AUTOSAR XML (schema 4-0-3)
package /DID_Component
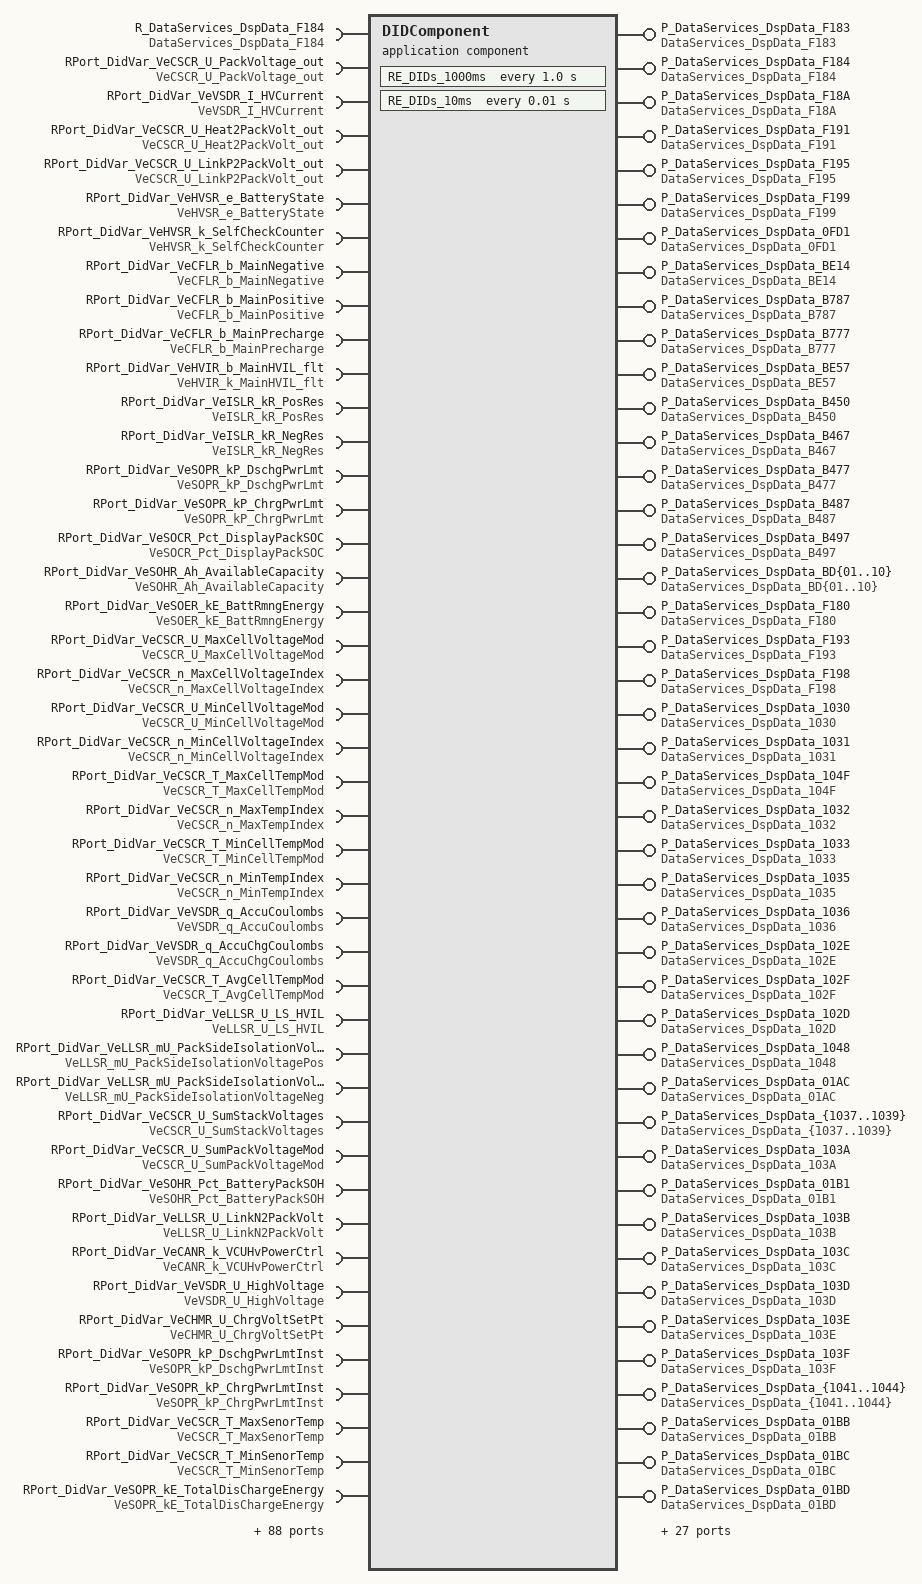
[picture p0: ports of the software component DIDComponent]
  application sw component type DIDComponent
    provide port P_DataServices_DspData_F183: provided-interface=DataServices_DspData_F183
    provide port P_DataServices_DspData_F184: provided-interface=DataServices_DspData_F184
    require port R_DataServices_DspData_F184: nonqueued-receiver-com-spec{data-element=Data, enable-update=true}, required-interface=DataServices_DspData_F184
    76 x provide port:
      P_DataServices_DspData_F18A: provided-interface=DataServices_DspData_F18A
      P_DataServices_DspData_F191: provided-interface=DataServices_DspData_F191
      P_DataServices_DspData_F195: provided-interface=DataServices_DspData_F195
      P_DataServices_DspData_F199: provided-interface=DataServices_DspData_F199
      P_DataServices_DspData_0FD1: provided-interface=DataServices_DspData_0FD1
      P_DataServices_DspData_BE14: provided-interface=DataServices_DspData_BE14
      P_DataServices_DspData_B787: provided-interface=DataServices_DspData_B787
      P_DataServices_DspData_B777: provided-interface=DataServices_DspData_B777
      P_DataServices_DspData_BE57: provided-interface=DataServices_DspData_BE57
      P_DataServices_DspData_B450: provided-interface=DataServices_DspData_B450
      P_DataServices_DspData_B467: provided-interface=DataServices_DspData_B467
      P_DataServices_DspData_B477: provided-interface=DataServices_DspData_B477
      P_DataServices_DspData_B487: provided-interface=DataServices_DspData_B487
      P_DataServices_DspData_B497: provided-interface=DataServices_DspData_B497
      P_DataServices_DspData_BD{01..10}: provided-interface=DataServices_DspData_BD{01..10}
      P_DataServices_DspData_F180: provided-interface=DataServices_DspData_F180
      P_DataServices_DspData_F193: provided-interface=DataServices_DspData_F193
      P_DataServices_DspData_F198: provided-interface=DataServices_DspData_F198
      P_DataServices_DspData_1030: provided-interface=DataServices_DspData_1030
      P_DataServices_DspData_1031: provided-interface=DataServices_DspData_1031
      P_DataServices_DspData_104F: provided-interface=DataServices_DspData_104F
      P_DataServices_DspData_1032: provided-interface=DataServices_DspData_1032
      P_DataServices_DspData_1033: provided-interface=DataServices_DspData_1033
      P_DataServices_DspData_1035: provided-interface=DataServices_DspData_1035
      P_DataServices_DspData_1036: provided-interface=DataServices_DspData_1036
      P_DataServices_DspData_102E: provided-interface=DataServices_DspData_102E
      P_DataServices_DspData_102F: provided-interface=DataServices_DspData_102F
      P_DataServices_DspData_102D: provided-interface=DataServices_DspData_102D
      P_DataServices_DspData_1048: provided-interface=DataServices_DspData_1048
      P_DataServices_DspData_01AC: provided-interface=DataServices_DspData_01AC
      P_DataServices_DspData_{1037..1039}: provided-interface=DataServices_DspData_{1037..1039}
      P_DataServices_DspData_103A: provided-interface=DataServices_DspData_103A
      P_DataServices_DspData_01B1: provided-interface=DataServices_DspData_01B1
      P_DataServices_DspData_103B: provided-interface=DataServices_DspData_103B
      P_DataServices_DspData_103C: provided-interface=DataServices_DspData_103C
      P_DataServices_DspData_103D: provided-interface=DataServices_DspData_103D
      P_DataServices_DspData_103E: provided-interface=DataServices_DspData_103E
      P_DataServices_DspData_103F: provided-interface=DataServices_DspData_103F
      P_DataServices_DspData_{1041..1044}: provided-interface=DataServices_DspData_{1041..1044}
      P_DataServices_DspData_01BB: provided-interface=DataServices_DspData_01BB
      P_DataServices_DspData_01BC: provided-interface=DataServices_DspData_01BC
      P_DataServices_DspData_01BD: provided-interface=DataServices_DspData_01BD
      P_DataServices_DspData_01BE: provided-interface=DataServices_DspData_01BE
      P_DataServices_DspData_01BF: provided-interface=DataServices_DspData_01BF
      P_DataServices_DspData_01C0: provided-interface=DataServices_DspData_01C0
      P_DataServices_DspData_{1045..1047}: provided-interface=DataServices_DspData_{1045..1047}
      P_DataServices_DspData_01D9: provided-interface=DataServices_DspData_01D9
      P_DataServices_DspData_01DA: provided-interface=DataServices_DspData_01DA
      P_DataServices_DspData_01DC: provided-interface=DataServices_DspData_01DC
      P_DataServices_DspData_01DD: provided-interface=DataServices_DspData_01DD
      P_DataServices_DspData_01E4: provided-interface=DataServices_DspData_01E4
      P_DataServices_DspData_01E5: provided-interface=DataServices_DspData_01E5
      P_DataServices_DspData_1049: provided-interface=DataServices_DspData_1049
      P_DataServices_DspData_01E{7..9}: provided-interface=DataServices_DspData_01E{7..9}
      P_DataServices_DspData_01EA: provided-interface=DataServices_DspData_01EA
      P_DataServices_DspData_104A: provided-interface=DataServices_DspData_104A
      P_DataServices_DspData_104B: provided-interface=DataServices_DspData_104B
      P_DataServices_DspData_104E: provided-interface=DataServices_DspData_104E
    34 x require port:
      RPort_DidVar_VeCSCR_U_PackVoltage_out: required-interface=VeCSCR_U_PackVoltage_out
      RPort_DidVar_VeVSDR_I_HVCurrent: required-interface=VeVSDR_I_HVCurrent
      RPort_DidVar_VeCSCR_U_Heat2PackVolt_out: required-interface=VeCSCR_U_Heat2PackVolt_out
      RPort_DidVar_VeCSCR_U_LinkP2PackVolt_out: required-interface=VeCSCR_U_LinkP2PackVolt_out
      RPort_DidVar_VeHVSR_e_BatteryState: required-interface=VeHVSR_e_BatteryState
      RPort_DidVar_VeHVSR_k_SelfCheckCounter: required-interface=VeHVSR_k_SelfCheckCounter
      RPort_DidVar_VeCFLR_b_MainNegative: required-interface=VeCFLR_b_MainNegative
      RPort_DidVar_VeCFLR_b_MainPositive: required-interface=VeCFLR_b_MainPositive
      RPort_DidVar_VeCFLR_b_MainPrecharge: required-interface=VeCFLR_b_MainPrecharge
      RPort_DidVar_VeHVIR_b_MainHVIL_flt: required-interface=VeHVIR_k_MainHVIL_flt
      RPort_DidVar_VeISLR_kR_PosRes: required-interface=VeISLR_kR_PosRes
      RPort_DidVar_VeISLR_kR_NegRes: required-interface=VeISLR_kR_NegRes
      RPort_DidVar_VeSOPR_kP_DschgPwrLmt: required-interface=VeSOPR_kP_DschgPwrLmt
      RPort_DidVar_VeSOPR_kP_ChrgPwrLmt: required-interface=VeSOPR_kP_ChrgPwrLmt
      RPort_DidVar_VeSOCR_Pct_DisplayPackSOC: required-interface=VeSOCR_Pct_DisplayPackSOC
      RPort_DidVar_VeSOHR_Ah_AvailableCapacity: required-interface=VeSOHR_Ah_AvailableCapacity
      RPort_DidVar_VeSOER_kE_BattRmngEnergy: required-interface=VeSOER_kE_BattRmngEnergy
      RPort_DidVar_VeCSCR_U_MaxCellVoltageMod: required-interface=VeCSCR_U_MaxCellVoltageMod
      RPort_DidVar_VeCSCR_n_MaxCellVoltageIndex: required-interface=VeCSCR_n_MaxCellVoltageIndex
      RPort_DidVar_VeCSCR_U_MinCellVoltageMod: required-interface=VeCSCR_U_MinCellVoltageMod
      RPort_DidVar_VeCSCR_n_MinCellVoltageIndex: required-interface=VeCSCR_n_MinCellVoltageIndex
      RPort_DidVar_VeCSCR_T_MaxCellTempMod: required-interface=VeCSCR_T_MaxCellTempMod
      RPort_DidVar_VeCSCR_n_MaxTempIndex: required-interface=VeCSCR_n_MaxTempIndex
      RPort_DidVar_VeCSCR_T_MinCellTempMod: required-interface=VeCSCR_T_MinCellTempMod
      RPort_DidVar_VeCSCR_n_MinTempIndex: required-interface=VeCSCR_n_MinTempIndex
      RPort_DidVar_VeVSDR_q_AccuCoulombs: required-interface=VeVSDR_q_AccuCoulombs
      RPort_DidVar_VeVSDR_q_AccuChgCoulombs: required-interface=VeVSDR_q_AccuChgCoulombs
      RPort_DidVar_VeCSCR_T_AvgCellTempMod: required-interface=VeCSCR_T_AvgCellTempMod
      RPort_DidVar_VeLLSR_U_LS_HVIL: required-interface=VeLLSR_U_LS_HVIL
      RPort_DidVar_VeLLSR_mU_PackSideIsolationVoltagePos: required-interface=VeLLSR_mU_PackSideIsolationVoltagePos
      RPort_DidVar_VeLLSR_mU_PackSideIsolationVoltageNeg: required-interface=VeLLSR_mU_PackSideIsolationVoltageNeg
      RPort_DidVar_VeCSCR_U_SumStackVoltages: required-interface=VeCSCR_U_SumStackVoltages
      RPort_DidVar_VeCSCR_U_SumPackVoltageMod: required-interface=VeCSCR_U_SumPackVoltageMod
      RPort_DidVar_VeSOHR_Pct_BatteryPackSOH: required-interface=VeSOHR_Pct_BatteryPackSOH
    4 x provide port:
      PPort_DID_F1F0: provided-interface=DataServices_DcmDspData_F1F0
      PPort_DID_F1AA: provided-interface=DataServices_DcmDspData_F1AA
      PPort_DID_F1A9: provided-interface=DataServices_DcmDspData_F1A9
      PPort_DID_F1A5: provided-interface=DataServices_DcmDspData_F1A5
    16 x require port:
      RPort_DidVar_VeLLSR_U_LinkN2PackVolt: required-interface=VeLLSR_U_LinkN2PackVolt
      RPort_DidVar_VeCANR_k_VCUHvPowerCtrl: required-interface=VeCANR_k_VCUHvPowerCtrl
      RPort_DidVar_VeVSDR_U_HighVoltage: required-interface=VeVSDR_U_HighVoltage
      RPort_DidVar_VeCHMR_U_ChrgVoltSetPt: required-interface=VeCHMR_U_ChrgVoltSetPt
      RPort_DidVar_VeSOPR_kP_DschgPwrLmtInst: required-interface=VeSOPR_kP_DschgPwrLmtInst
      RPort_DidVar_VeSOPR_kP_ChrgPwrLmtInst: required-interface=VeSOPR_kP_ChrgPwrLmtInst
      RPort_DidVar_VeCSCR_T_MaxSenorTemp: required-interface=VeCSCR_T_MaxSenorTemp
      RPort_DidVar_VeCSCR_T_MinSenorTemp: required-interface=VeCSCR_T_MinSenorTemp
      RPort_DidVar_VeSOPR_kE_TotalDisChargeEnergy: required-interface=VeSOPR_kE_TotalDisChargeEnergy
      RPort_DidVar_VeSOPR_kE_TotalChargeEnergy: required-interface=VeSOPR_kE_TotalChargeEnergy
      RPort_DidVar_VeLLSR_b_VCU_Wake: required-interface=VeLLSR_b_VCU_Wake
      RPort_DidVar_VeLLSR_U_KL30Volt: required-interface=VeLLSR_U_KL30Volt
      RPort_DidVar_VeISLR_kR_IsolationResistance: required-interface=VeISLR_kR_InsolationResistance
      RPort_DidVar_VeLLSR_U_HS_HVIL: required-interface=VeLLSR_U_HS_HVIL
      RPort_DidVar_VaCLBR_b_ActivateBalancing: required-interface=VaCLBR_b_ActivateBalancing
      RPort_DidVar_VeLLSR_U_HS_FCHVIL: required-interface=VeLLSR_U_HS_FCHVIL
    6 x provide port:
      P_DataServices_DspData_F192: provided-interface=DataServices_DspData_F192
      P_DataServices_DspData_F188: provided-interface=DataServices_DspData_F188
      P_DataServices_DspData_1000: provided-interface=DataServices_DspData_1000
      P_DataServices_DspData_1020: provided-interface=DataServices_DspData_1020
      P_DataServices_DspData_1040: provided-interface=DataServices_DspData_1040
      P_DataServices_DspData_1034: provided-interface=DataServices_DspData_1034
    4 x require port:
      RPort_DidVar_VeHVSR_k_BMSSts: required-interface=VeHVSR_k_BMSSts
      RPort_DidVar_VeCHMR_I_ChrgCurrentMax: required-interface=VeCHMR_I_ChrgCurrentMax
      RPort_DidVar_VeSOPR_kE_SingleDisChargeEnergy: required-interface=VeSOPR_kE_SingleDisChargeEnergy
      RPort_DidVar_VeSOPR_kE_SingleChargeEnergy: required-interface=VeSOPR_kE_SingleChargeEnergy
    provide port P_DataServices_DspData_F194: provided-interface=DataServices_DspData_F194
    77 x require port:
      RPort_DidVar_VeCPLR_k_DeltaCV_L2_flt: required-interface=VeCPLR_k_DeltaCV_L2_flt
      RPort_DidVar_VeCPLR_k_DeltaCV_L1_flt: required-interface=VeCPLR_k_DeltaCV_L1_flt
      RPort_DidVar_VeCPLR_k_UnderCV_L4_flt: required-interface=VeCPLR_k_UnderCV_L4_flt
      RPort_DidVar_VeCPLR_k_UnderCV_L3_flt: required-interface=VeCPLR_k_UnderCV_L3_flt
      RPort_DidVar_VeCPLR_k_UnderCV_L2_flt: required-interface=VeCPLR_k_UnderCV_L2_flt
      RPort_DidVar_VeCPLR_k_OverCV_L4_flt: required-interface=VeCPLR_k_OverCV_L4_flt
      RPort_DidVar_VeCPLR_k_OverCV_L3_flt: required-interface=VeCPLR_k_OverCV_L3_flt
      RPort_DidVar_VeCPLR_k_OverCV_L1_flt: required-interface=VeCPLR_k_OverCV_L1_flt
      RPort_DidVar_VeCPLR_k_OverCT_L4_flt: required-interface=VeCPLR_k_OverCT_L4_flt
      RPort_DidVar_VeCPLR_k_OverCT_L3_flt: required-interface=VeCPLR_k_OverCT_L3_flt
      RPort_DidVar_VeCPLR_k_OverCT_L1_flt: required-interface=VeCPLR_k_OverCT_L1_flt
      RPort_DidVar_VeCPLR_k_PackUnderVolt_L3_flt: required-interface=VeCPLR_k_PackUnderVolt_L3_flt
      RPort_DidVar_VeCPLR_k_PackUnderVolt_L2_flt: required-interface=VeCPLR_k_PackUnderVolt_L2_flt
      RPort_DidVar_VeCPLR_k_PackOverVolt_L3_flt: required-interface=VeCPLR_k_PackOverVolt_L3_flt
      RPort_DidVar_VeCPLR_k_PackOverVolt_L1_flt: required-interface=VeCPLR_k_PackOverVolt_L1_flt
      RPort_DidVar_VeCPLR_k_DeltaCV_L3_flt: required-interface=VeCPLR_k_DeltaCV_L3_flt
      RPort_DidVar_VeSOPR_k_PackOverDchrgPower2_flt: required-interface=VeSOPR_k_PackOverDchrgPower2_flt
      RPort_DidVar_VeSOPR_k_PackOverDchrgPower1_flt: required-interface=VeSOPR_k_PackOverDchrgPower1_flt
      RPort_DidVar_VeCPLR_k_DeltaCT_L3_flt: required-interface=VeCPLR_k_DeltaCT_L3_flt
      RPort_DidVar_VeCPLR_k_DeltaCT_L2_flt: required-interface=VeCPLR_k_DeltaCT_L2_flt
      RPort_DidVar_VeCPLR_k_DeltaCT_L1_flt: required-interface=VeCPLR_k_DeltaCT_L1_flt
      RPort_DidVar_VeCPLR_k_UnderCT_L4_flt: required-interface=VeCPLR_k_UnderCT_L4_flt
      RPort_DidVar_VeCPLR_k_UnderCT_L3_flt: required-interface=VeCPLR_k_UnderCT_L3_flt
      RPort_DidVar_VeCPLR_k_UnderCT_L1_flt: required-interface=VeCPLR_k_UnderCT_L1_flt
      RPort_DidVar_VeSOCR_k_SOC_low3_flt: required-interface=VeSOCR_k_SOC_low3_flt
      RPort_DidVar_VeSOCR_k_SOC_low2_flt: required-interface=VeSOCR_k_SOC_low2_flt
      RPort_DidVar_VeSOCR_k_SOC_low1_flt: required-interface=VeSOCR_k_SOC_low1_flt
      RPort_DidVar_VeCHMR_k_ChrgOverCurr_level3_flt: required-interface=VeCHMR_k_ChrgOverCurr_level3_flt
      RPort_DidVar_VeSOPR_k_PackOverChrgPower3_flt: required-interface=VeSOPR_k_PackOverChrgPower3_flt
      RPort_DidVar_VeSOPR_k_PackOverChrgPower2_flt: required-interface=VeSOPR_k_PackOverChrgPower2_flt
      RPort_DidVar_VeSOPR_k_PackOverChrgPower1_flt: required-interface=VeSOPR_k_PackOverChrgPower1_flt
      RPort_DidVar_VeSOPR_k_PackOverDchrgPower3_flt: required-interface=VeSOPR_k_PackOverDchrgPower3_flt
      RPort_DidVar_VeCSCR_k_StackCircuit_flt: required-interface=VeCSCR_k_StackCircuit_flt
      RPort_DidVar_VeCSCR_k_CellCircuit_flt: required-interface=VeCSCR_k_CellCircuit_flt
      RPort_DidVar_VeISLR_k_Isolation_flt: required-interface=VeISLR_k_Isolation_flt
      RPort_DidVar_VeISLR_k_Isolation_L2_flt: required-interface=VeISLR_k_Isolation_L2_flt
      RPort_DidVar_VeISLR_k_Isolation_L1_flt: required-interface=VeISLR_k_Isolation_L1_flt
      RPort_DidVar_VeSOCR_k_SOCOverWarn_flt: required-interface=VeSOCR_k_SOCOverWarn_flt
      RPort_DidVar_VeSOCR_k_SOCJumpWarn_flt: required-interface=VeSOCR_k_SOCJumpWarn_flt
      RPort_DidVar_VeSOHR_k_LowSOH_flt: required-interface=VeSOHR_k_LowSOH_flt
      RPort_DidVar_VeLLSR_k_DaisyCom_flt: required-interface=VeLLSR_k_DaisyCom_flt
      RPort_DidVar_VeLLSR_k_BMS_CrashOutputSts: required-interface=VeLLSR_k_BMS_CrashOutputSts
      RPort_DidVar_VeLLSR_k_PackCrntCircuit_flt: required-interface=VeLLSR_k_PackCrntCircuit_flt
      RPort_DidVar_VeCSCR_k_TempArray_flt: required-interface=VeCSCR_k_TempArray_flt
      RPort_DidVar_VeCFLR_k_NegativeStuckClose_flt: required-interface=VeCFLR_k_NegativeStuckClose_flt
      RPort_DidVar_VeCFLR_k_ConDrvPosCircuit_flt: required-interface=VeCFLR_k_ConDrvPosCircuit_flt
      RPort_DidVar_VeCFLR_k_PositiveStuckOpen_flt: required-interface=VeCFLR_k_PositiveStuckOpen_flt
      RPort_DidVar_VeCFLR_k_PositiveStuckClose_flt: required-interface=VeCFLR_k_PositiveStuckClose_flt
      RPort_DidVar_VeCFLR_k_ConDrvHeatCircuit_flt: required-interface=VeCFLR_k_ConDrvHeatCircuit_flt
      RPort_DidVar_VeCFLR_k_HeatStuckOpen_flt: required-interface=VeCFLR_k_HeatStuckOpen_flt
      RPort_DidVar_VeCFLR_k_HeatStuckClose_flt: required-interface=VeCFLR_k_HeatStuckClose_flt
      RPort_DidVar_VeCFLR_k_ConDrvPreCircuit_flt: required-interface=VeCFLR_k_ConDrvPreCircuit_flt
      RPort_DidVar_VeCFLR_k_PrechargeStuckOpen_flt: required-interface=VeCFLR_k_PrechargeStuckOpen_flt
      RPort_DidVar_VeCFLR_k_PrechargeStuckClose_flt: required-interface=VeCFLR_k_PrechargeStuckClose_flt
      RPort_DidVar_VeCFLR_k_ConDrvNegCircuit_flt: required-interface=VeCFLR_k_ConDrvNegCircuit_flt
      RPort_DidVar_VeCFLR_k_NegativeStuckOpen_flt: required-interface=VeCFLR_k_NegativeStuckOpen_flt
      RPort_DidVar_VeCSCR_k_LinkNVolt_flt: required-interface=VeCSCR_k_LinkNVolt_flt
      RPort_DidVar_VeCSCR_k_HeatVolt_flt: required-interface=VeCSCR_k_HeatVolt_flt
      RPort_DidVar_VeCSCR_k_LinkPVolt_flt: required-interface=VeCSCR_k_LinkPVolt_flt
      RPort_DidVar_VeCSCR_k_PackVolt_flt: required-interface=VeCSCR_k_PackVolt_flt
      RPort_DidVar_VeLLSR_k_ExtEEP_flt: required-interface=VeLLSR_k_ExtEEP_flt
      RPort_DidVar_VeLLSR_k_IntEEP_flt: required-interface=VeLLSR_k_IntEEP_flt
      RPort_DidVar_VeCFLR_k_MainFuse2Open_flt: required-interface=VeCFLR_k_MainFuse2Open_flt
      RPort_DidVar_VeCFLR_k_MainFuse1Open_flt: required-interface=VeCFLR_k_MainFuse1Open_flt
      RPort_DidVar_VeCPLR_k_PCBOverTemp_flt: required-interface=VeCPLR_k_PCBOverTemp_flt
      RPort_DidVar_VeCSCR_k_PCBTempInv_Flt: required-interface=VeCSCR_k_PCBTempInv_Flt
      RPort_DidVar_VeLLSR_k_BalOverTemp_flt: required-interface=VeLLSR_k_BalOverTemp_flt
      RPort_DidVar_VeCSCR_k_CBCircuit_flt: required-interface=VeCSCR_k_CBCircuit_flt
      RPort_DidVar_VeCFLR_k_PreChargeFail_flt: required-interface=VeCFLR_k_PreChargeFail_flt
      RPort_DidVar_VeCFLR_k_PreResistorStuckOpen_flt: required-interface=VeCFLR_k_PreResistorStuckOpen_flt
      RPort_DidVar_VeVSDR_k_PackVoltageInRange_flt: required-interface=VeVSDR_k_PackVoltageInRange_flt
      RPort_DidVar_VeVSDR_k_LinkVoltageInRange_flt: required-interface=VeVSDR_k_LinkVoltageInRange_flt
      RPort_DidVar_VeHVIR_k_MainHVIL2_flt: required-interface=VeHVIR_k_MainHVIL2_flt
      RPort_DidVar_VeTHMR_k_HeatTempRiseFast_flt: required-interface=VeTHMR_k_HeatTempRiseFast_flt
      RPort_DidVar_VeCPLR_k_ThermalRunaway_flt: required-interface=VeCPLR_k_ThermalRunaway_flt
      RPort_DidVar_VeLLSR_k_AbnormalShutdownDetected: required-interface=VeLLSR_k_AbnormalShutdownDetected
      RPort_DidVar_VeCFLR_k_UnexpectedContOpen_flt: required-interface=VeCFLR_k_UnexpectedContOpen_flt
    behavior IB_DIDCmpt: data-type-mapping=[HVIR_CodeDataTypeMappingsSet, ISLR_CodeDataTypeMappingsSet, VSDR_CodeDataTypeMappingsSet, CLBR_CodeDataTypeMappingsSet, SOER_CodeDataTypeMappingsSet, SOPR_CodeDataTypeMappingsSet, CSCR_CodeDataTypeMappingsSet, HMIR_CodeDataTypeMappingsSet, CFLR_CodeDataTypeMappingsSet, DHSR_CodeDataTypeMappingsSet, SOCR_CodeDataTypeMappingsSet, SOHR_CodeDataTypeMappingsSet, HVSR_CodeDataTypeMappingsSet, CHMR_CodeDataTypeMappingsSet, CPLR_CodeDataTypeMappingsSet, THMR_CodeDataTypeMappingsSet]
      timing event TimingEvent_DIDs_1000ms: start-on-event=RE_DIDs_1000ms, period=1.0
      timing event TimingEvent_DIDs_10ms: start-on-event=RE_DIDs_10ms, period=0.01
      per instance memory PIM_Did_01FF: implementation-data-type=DcmDspDidSize_DspData_01FF, type=NeDIDR_PartNo_01FF, type-definition=DcmDspDidSize_DspData_01FF
      runnable RE_DIDs_1000ms: symbol=RE_DID_Process1000ms
        data-read-access:
          131 x access:
            DataReadPoints_VeCSCR_U_PackVoltage_out: accessed-variable=RPort_DidVar_VeCSCR_U_PackVoltage_out.VeCSCR_U_PackVoltage_out
            DataReadPoints_VeVSDR_I_HVCurrent: accessed-variable=RPort_DidVar_VeVSDR_I_HVCurrent.VeVSDR_I_HVCurrent
            DataReadPoints_VeCSCR_U_Heat2PackVolt_out: accessed-variable=RPort_DidVar_VeCSCR_U_Heat2PackVolt_out.VeCSCR_U_Heat2PackVolt_out
            DataReadPoints_VeCSCR_U_LinkP2PackVolt_out: accessed-variable=RPort_DidVar_VeCSCR_U_LinkP2PackVolt_out.VeCSCR_U_LinkP2PackVolt_out
            DataReadPoints_VeHVSR_e_BatteryState: accessed-variable=RPort_DidVar_VeHVSR_e_BatteryState.VeHVSR_e_BatteryState
            DataReadPoints_VeHVSR_k_SelfCheckCounter: accessed-variable=RPort_DidVar_VeHVSR_k_SelfCheckCounter.VeHVSR_k_SelfCheckCounter
            DataReadPoints_VeCFLR_b_MainNegative: accessed-variable=RPort_DidVar_VeCFLR_b_MainNegative.VeCFLR_b_MainNegative
            DataReadPoints_VeCFLR_b_MainPositive: accessed-variable=RPort_DidVar_VeCFLR_b_MainPositive.VeCFLR_b_MainPositive
            DataReadPoints_VeCFLR_b_MainPrecharge: accessed-variable=RPort_DidVar_VeCFLR_b_MainPrecharge.VeCFLR_b_MainPrecharge
            DataReadPoints_VeHVIR_b_MainHVIL_flt: accessed-variable=RPort_DidVar_VeHVIR_b_MainHVIL_flt.VeHVIR_k_MainHVIL_flt
            DataReadPoints_VeISLR_kR_PosRes: accessed-variable=RPort_DidVar_VeISLR_kR_PosRes.VeISLR_kR_PosRes
            DataReadPoints_VeISLR_kR_NegRes: accessed-variable=RPort_DidVar_VeISLR_kR_NegRes.VeISLR_kR_NegRes
            DataReadPoints_VeSOPR_kP_DschgPwrLmt: accessed-variable=RPort_DidVar_VeSOPR_kP_DschgPwrLmt.VeSOPR_kP_DschgPwrLmt
            DataReadPoints_VeSOPR_kP_ChrgPwrLmt: accessed-variable=RPort_DidVar_VeSOPR_kP_ChrgPwrLmt.VeSOPR_kP_ChrgPwrLmt
            DataReadPoints_VeSOCR_Pct_DisplayPackSOC: accessed-variable=RPort_DidVar_VeSOCR_Pct_DisplayPackSOC.VeSOCR_Pct_DisplayPackSOC
            DataReadPoints_VeSOHR_Ah_AvailableCapacity: accessed-variable=RPort_DidVar_VeSOHR_Ah_AvailableCapacity.VeSOHR_Ah_AvailableCapacity
            DataReadPoints_VeSOER_kE_BattRmngEnergy: accessed-variable=RPort_DidVar_VeSOER_kE_BattRmngEnergy.VeSOER_kE_BattRmngEnergy
            DataReadPoints_VeCSCR_U_MaxCellVoltageMod: accessed-variable=RPort_DidVar_VeCSCR_U_MaxCellVoltageMod.VeCSCR_U_MaxCellVoltageMod
            DataReadPoints_VeCSCR_n_MaxCellVoltageIndex: accessed-variable=RPort_DidVar_VeCSCR_n_MaxCellVoltageIndex.VeCSCR_n_MaxCellVoltageIndex
            DataReadPoints_VeCSCR_U_MinCellVoltageMod: accessed-variable=RPort_DidVar_VeCSCR_U_MinCellVoltageMod.VeCSCR_U_MinCellVoltageMod
            DataReadPoints_VeCSCR_n_MinCellVoltageIndex: accessed-variable=RPort_DidVar_VeCSCR_n_MinCellVoltageIndex.VeCSCR_n_MinCellVoltageIndex
            DataReadPoints_VeCSCR_T_MaxCellTempMod: accessed-variable=RPort_DidVar_VeCSCR_T_MaxCellTempMod.VeCSCR_T_MaxCellTempMod
            DataReadPoints_VeCSCR_n_MaxTempIndex: accessed-variable=RPort_DidVar_VeCSCR_n_MaxTempIndex.VeCSCR_n_MaxTempIndex
            DataReadPoints_VeCSCR_T_MinCellTempMod: accessed-variable=RPort_DidVar_VeCSCR_T_MinCellTempMod.VeCSCR_T_MinCellTempMod
            DataReadPoints_VeCSCR_n_MinTempIndex: accessed-variable=RPort_DidVar_VeCSCR_n_MinTempIndex.VeCSCR_n_MinTempIndex
            DataReadPoints_VeVSDR_q_AccuCoulombs: accessed-variable=RPort_DidVar_VeVSDR_q_AccuCoulombs.VeVSDR_q_AccuCoulombs
            DataReadPoints_VeVSDR_q_AccuChgCoulombs: accessed-variable=RPort_DidVar_VeVSDR_q_AccuChgCoulombs.VeVSDR_q_AccuChgCoulombs
            DataReadPoints_VeCSCR_T_AvgCellTempMod: accessed-variable=RPort_DidVar_VeCSCR_T_AvgCellTempMod.VeCSCR_T_AvgCellTempMod
            DataReadPoints_VeLLSR_U_LS_HVIL: accessed-variable=RPort_DidVar_VeLLSR_U_LS_HVIL.VeLLSR_U_LS_HVIL
            DataReadPoints_VeLLSR_mU_PackSideIsolationVoltagePos: accessed-variable=RPort_DidVar_VeLLSR_mU_PackSideIsolationVoltagePos.VeLLSR_mU_PackSideIsolationVoltagePos
            DataReadPoints_VeLLSR_mU_PackSideIsolationVoltageNeg: accessed-variable=RPort_DidVar_VeLLSR_mU_PackSideIsolationVoltageNeg.VeLLSR_mU_PackSideIsolationVoltageNeg
            DataReadPoints_VeCSCR_U_SumStackVoltages: accessed-variable=RPort_DidVar_VeCSCR_U_SumStackVoltages.VeCSCR_U_SumStackVoltages
            DataReadPoints_VeCSCR_U_SumPackVoltageMod: accessed-variable=RPort_DidVar_VeCSCR_U_SumPackVoltageMod.VeCSCR_U_SumPackVoltageMod
            DataReadPoints_VeSOHR_Pct_BatteryPackSOH: accessed-variable=RPort_DidVar_VeSOHR_Pct_BatteryPackSOH.VeSOHR_Pct_BatteryPackSOH
            DRA_VeLLSR_U_LinkN2PackVolt_0: accessed-variable=RPort_DidVar_VeLLSR_U_LinkN2PackVolt.VeLLSR_U_LinkN2PackVolt
            DRA_VeCANR_k_VCUHvPowerCtrl_0: accessed-variable=RPort_DidVar_VeCANR_k_VCUHvPowerCtrl.VeCANR_k_VCUHvPowerCtrl
            DRA_VeVSDR_U_HighVoltage_0: accessed-variable=RPort_DidVar_VeVSDR_U_HighVoltage.VeVSDR_U_HighVoltage
            DRA_VeCHMR_U_ChrgVoltSetPt_0: accessed-variable=RPort_DidVar_VeCHMR_U_ChrgVoltSetPt.VeCHMR_U_ChrgVoltSetPt
            DRA_VeSOPR_kP_DschgPwrLmtInst_0: accessed-variable=RPort_DidVar_VeSOPR_kP_DschgPwrLmtInst.VeSOPR_kP_DschgPwrLmtInst
            DRA_VeSOPR_kP_ChrgPwrLmtInst_0: accessed-variable=RPort_DidVar_VeSOPR_kP_ChrgPwrLmtInst.VeSOPR_kP_ChrgPwrLmtInst
            DRA_VeCSCR_T_MaxSenorTemp_0: accessed-variable=RPort_DidVar_VeCSCR_T_MaxSenorTemp.VeCSCR_T_MaxSenorTemp
            DRA_VeCSCR_T_MinSenorTemp_0: accessed-variable=RPort_DidVar_VeCSCR_T_MinSenorTemp.VeCSCR_T_MinSenorTemp
            DRA_VeSOPR_kE_TotalDisChargeEnergy_0: accessed-variable=RPort_DidVar_VeSOPR_kE_TotalDisChargeEnergy.VeSOPR_kE_TotalDisChargeEnergy
            DRA_VeSOPR_kE_TotalChargeEnergy_0: accessed-variable=RPort_DidVar_VeSOPR_kE_TotalChargeEnergy.VeSOPR_kE_TotalChargeEnergy
            DRA_VeLLSR_b_VCU_Wake_0: accessed-variable=RPort_DidVar_VeLLSR_b_VCU_Wake.VeLLSR_b_VCU_Wake
            DRA_VeLLSR_U_KL30Volt_0: accessed-variable=RPort_DidVar_VeLLSR_U_KL30Volt.VeLLSR_U_KL30Volt
            DRA_VeISLR_kR_InsolationResistance_0: accessed-variable=RPort_DidVar_VeISLR_kR_IsolationResistance.VeISLR_kR_InsolationResistance
            DRA_VeLLSR_U_HS_HVIL_0: accessed-variable=RPort_DidVar_VeLLSR_U_HS_HVIL.VeLLSR_U_HS_HVIL
            DRA_VaCLBR_b_ActivateBalancing_0: accessed-variable=RPort_DidVar_VaCLBR_b_ActivateBalancing.VaCLBR_b_ActivateBalancing
            DRA_VeLLSR_U_HS_FCHVIL_0: accessed-variable=RPort_DidVar_VeLLSR_U_HS_FCHVIL.VeLLSR_U_HS_FCHVIL
            DRA_VeHVSR_k_BMSSts_0: accessed-variable=RPort_DidVar_VeHVSR_k_BMSSts.VeHVSR_k_BMSSts
            DRA_VeCHMR_I_ChrgCurrentMax_0: accessed-variable=RPort_DidVar_VeCHMR_I_ChrgCurrentMax.VeCHMR_I_ChrgCurrentMax
            DRA_VeSOPR_kE_SingleChargeEnergy_0: accessed-variable=RPort_DidVar_VeSOPR_kE_SingleChargeEnergy.VeSOPR_kE_SingleChargeEnergy
            DRA_VeSOPR_kE_SingleDisChargeEnergy_0: accessed-variable=RPort_DidVar_VeSOPR_kE_SingleDisChargeEnergy.VeSOPR_kE_SingleDisChargeEnergy
            DRA_VeCPLR_k_DeltaCV_L2_flt_0: accessed-variable=RPort_DidVar_VeCPLR_k_DeltaCV_L2_flt.VeCPLR_k_DeltaCV_L2_flt
            DRA_VeSOCR_k_SOC_low2_flt_0: accessed-variable=RPort_DidVar_VeSOCR_k_SOC_low2_flt.VeSOCR_k_SOC_low2_flt
            DRA_VeLLSR_k_BMS_CrashOutputSts_0: accessed-variable=RPort_DidVar_VeLLSR_k_BMS_CrashOutputSts.VeLLSR_k_BMS_CrashOutputSts
            DRA_VeCPLR_k_ThermalRunaway_flt_0: accessed-variable=RPort_DidVar_VeCPLR_k_ThermalRunaway_flt.VeCPLR_k_ThermalRunaway_flt
            DRA_VeCFLR_k_PositiveStuckOpen_flt_0: accessed-variable=RPort_DidVar_VeCFLR_k_PositiveStuckOpen_flt.VeCFLR_k_PositiveStuckOpen_flt
            DRA_VeCPLR_k_OverCT_L3_flt_0: accessed-variable=RPort_DidVar_VeCPLR_k_OverCT_L3_flt.VeCPLR_k_OverCT_L3_flt
            DRA_VeSOCR_k_SOC_low3_flt_0: accessed-variable=RPort_DidVar_VeSOCR_k_SOC_low3_flt.VeSOCR_k_SOC_low3_flt
            DRA_VeCSCR_k_StackCircuit_flt_0: accessed-variable=RPort_DidVar_VeCSCR_k_StackCircuit_flt.VeCSCR_k_StackCircuit_flt
            DRA_VeCPLR_k_DeltaCT_L1_flt_0: accessed-variable=RPort_DidVar_VeCPLR_k_DeltaCT_L1_flt.VeCPLR_k_DeltaCT_L1_flt
            DRA_VeCSCR_k_HeatVolt_flt_0: accessed-variable=RPort_DidVar_VeCSCR_k_HeatVolt_flt.VeCSCR_k_HeatVolt_flt
            DRA_VeVSDR_k_PackVoltageInRange_flt_0: accessed-variable=RPort_DidVar_VeVSDR_k_PackVoltageInRange_flt.VeVSDR_k_PackVoltageInRange_flt
            DRA_VeLLSR_k_AbnormalShutdownDetected_0: accessed-variable=RPort_DidVar_VeLLSR_k_AbnormalShutdownDetected.VeLLSR_k_AbnormalShutdownDetected
            DRA_VeCPLR_k_OverCV_L3_flt_0: accessed-variable=RPort_DidVar_VeCPLR_k_OverCV_L3_flt.VeCPLR_k_OverCV_L3_flt
            DRA_VeISLR_k_Isolation_flt_0: accessed-variable=RPort_DidVar_VeISLR_k_Isolation_flt.VeISLR_k_Isolation_flt
            DRA_VeSOCR_k_SOC_low1_flt_0: accessed-variable=RPort_DidVar_VeSOCR_k_SOC_low1_flt.VeSOCR_k_SOC_low1_flt
            DRA_VeCPLR_k_PCBOverTemp_flt_0: accessed-variable=RPort_DidVar_VeCPLR_k_PCBOverTemp_flt.VeCPLR_k_PCBOverTemp_flt
            DRA_VeCFLR_k_ConDrvPosCircuit_flt_0: accessed-variable=RPort_DidVar_VeCFLR_k_ConDrvPosCircuit_flt.VeCFLR_k_ConDrvPosCircuit_flt
            DRA_VeCFLR_k_UnexpectedContOpen_flt_0: accessed-variable=RPort_DidVar_VeCFLR_k_UnexpectedContOpen_flt.VeCFLR_k_UnexpectedContOpen_flt
            DRA_VeSOCR_k_SOCJumpWarn_flt_0: accessed-variable=RPort_DidVar_VeSOCR_k_SOCJumpWarn_flt.VeSOCR_k_SOCJumpWarn_flt
            DRA_VeCFLR_k_PreChargeFail_flt_0: accessed-variable=RPort_DidVar_VeCFLR_k_PreChargeFail_flt.VeCFLR_k_PreChargeFail_flt
            DRA_VeSOPR_k_PackOverDchrgPower1_flt_0: accessed-variable=RPort_DidVar_VeSOPR_k_PackOverDchrgPower1_flt.VeSOPR_k_PackOverDchrgPower1_flt
            DRA_VeCPLR_k_UnderCV_L4_flt_0: accessed-variable=RPort_DidVar_VeCPLR_k_UnderCV_L4_flt.VeCPLR_k_UnderCV_L4_flt
            DRA_VeISLR_k_Isolation_L2_flt_0: accessed-variable=RPort_DidVar_VeISLR_k_Isolation_L2_flt.VeISLR_k_Isolation_L2_flt
            DRA_VeCPLR_k_UnderCT_L4_flt_0: accessed-variable=RPort_DidVar_VeCPLR_k_UnderCT_L4_flt.VeCPLR_k_UnderCT_L4_flt
            DRA_VeCPLR_k_UnderCV_L3_flt_0: accessed-variable=RPort_DidVar_VeCPLR_k_UnderCV_L3_flt.VeCPLR_k_UnderCV_L3_flt
            DRA_VeISLR_k_Isolation_L1_flt_0: accessed-variable=RPort_DidVar_VeISLR_k_Isolation_L1_flt.VeISLR_k_Isolation_L1_flt
            DRA_VeCPLR_k_PackOverVolt_L3_flt_0: accessed-variable=RPort_DidVar_VeCPLR_k_PackOverVolt_L3_flt.VeCPLR_k_PackOverVolt_L3_flt
            DRA_VeLLSR_k_ExtEEP_flt_0: accessed-variable=RPort_DidVar_VeLLSR_k_ExtEEP_flt.VeLLSR_k_ExtEEP_flt
            DRA_VeCSCR_k_CellCircuit_flt_0: accessed-variable=RPort_DidVar_VeCSCR_k_CellCircuit_flt.VeCSCR_k_CellCircuit_flt
            DRA_VeCPLR_k_DeltaCV_L1_flt_0: accessed-variable=RPort_DidVar_VeCPLR_k_DeltaCV_L1_flt.VeCPLR_k_DeltaCV_L1_flt
            DRA_VeCPLR_k_OverCT_L1_flt_0: accessed-variable=RPort_DidVar_VeCPLR_k_OverCT_L1_flt.VeCPLR_k_OverCT_L1_flt
            DRA_VeVSDR_k_LinkVoltageInRange_flt_0: accessed-variable=RPort_DidVar_VeVSDR_k_LinkVoltageInRange_flt.VeVSDR_k_LinkVoltageInRange_flt
            DRA_VeSOPR_k_PackOverChrgPower1_flt_0: accessed-variable=RPort_DidVar_VeSOPR_k_PackOverChrgPower1_flt.VeSOPR_k_PackOverChrgPower1_flt
            DRA_VeSOPR_k_PackOverDchrgPower2_flt_0: accessed-variable=RPort_DidVar_VeSOPR_k_PackOverDchrgPower2_flt.VeSOPR_k_PackOverDchrgPower2_flt
            DRA_VeSOPR_k_PackOverDchrgPower3_flt_0: accessed-variable=RPort_DidVar_VeSOPR_k_PackOverDchrgPower3_flt.VeSOPR_k_PackOverDchrgPower3_flt
            DRA_VeLLSR_k_BalOverTemp_flt_0: accessed-variable=RPort_DidVar_VeLLSR_k_BalOverTemp_flt.VeLLSR_k_BalOverTemp_flt
            DRA_VeCPLR_k_DeltaCV_L3_flt_0: accessed-variable=RPort_DidVar_VeCPLR_k_DeltaCV_L3_flt.VeCPLR_k_DeltaCV_L3_flt
            DRA_VeLLSR_k_DaisyCom_flt_0: accessed-variable=RPort_DidVar_VeLLSR_k_DaisyCom_flt.VeLLSR_k_DaisyCom_flt
            DRA_VeCHMR_k_ChrgOverCurr_level3_flt_0: accessed-variable=RPort_DidVar_VeCHMR_k_ChrgOverCurr_level3_flt.VeCHMR_k_ChrgOverCurr_level3_flt
            DRA_VeSOPR_k_PackOverChrgPower3_flt_0: accessed-variable=RPort_DidVar_VeSOPR_k_PackOverChrgPower3_flt.VeSOPR_k_PackOverChrgPower3_flt
            DRA_VeCSCR_k_LinkNVolt_flt_0: accessed-variable=RPort_DidVar_VeCSCR_k_LinkNVolt_flt.VeCSCR_k_LinkNVolt_flt
            DRA_VeCPLR_k_DeltaCT_L3_flt_0: accessed-variable=RPort_DidVar_VeCPLR_k_DeltaCT_L3_flt.VeCPLR_k_DeltaCT_L3_flt
            DRA_VeCSCR_k_PackVolt_flt_0: accessed-variable=RPort_DidVar_VeCSCR_k_PackVolt_flt.VeCSCR_k_PackVolt_flt
            DRA_VeCFLR_k_ConDrvHeatCircuit_flt_0: accessed-variable=RPort_DidVar_VeCFLR_k_ConDrvHeatCircuit_flt.VeCFLR_k_ConDrvHeatCircuit_flt
            DRA_VeCSCR_k_CBCircuit_flt_0: accessed-variable=RPort_DidVar_VeCSCR_k_CBCircuit_flt.VeCSCR_k_CBCircuit_flt
            DRA_VeSOHR_k_LowSOH_flt_0: accessed-variable=RPort_DidVar_VeSOHR_k_LowSOH_flt.VeSOHR_k_LowSOH_flt
            DRA_VeCFLR_k_PositiveStuckClose_flt_0: accessed-variable=RPort_DidVar_VeCFLR_k_PositiveStuckClose_flt.VeCFLR_k_PositiveStuckClose_flt
            DRA_VeCFLR_k_NegativeStuckOpen_flt_0: accessed-variable=RPort_DidVar_VeCFLR_k_NegativeStuckOpen_flt.VeCFLR_k_NegativeStuckOpen_flt
            DRA_VeCFLR_k_ConDrvNegCircuit_flt_0: accessed-variable=RPort_DidVar_VeCFLR_k_ConDrvNegCircuit_flt.VeCFLR_k_ConDrvNegCircuit_flt
            DRA_VeSOCR_k_SOCOverWarn_flt_0: accessed-variable=RPort_DidVar_VeSOCR_k_SOCOverWarn_flt.VeSOCR_k_SOCOverWarn_flt
            DRA_VeLLSR_k_PackCrntCircuit_flt_0: accessed-variable=RPort_DidVar_VeLLSR_k_PackCrntCircuit_flt.VeLLSR_k_PackCrntCircuit_flt
            DRA_VeCFLR_k_HeatStuckOpen_flt_0: accessed-variable=RPort_DidVar_VeCFLR_k_HeatStuckOpen_flt.VeCFLR_k_HeatStuckOpen_flt
            DRA_VeCPLR_k_PackUnderVolt_L3_flt_0: accessed-variable=RPort_DidVar_VeCPLR_k_PackUnderVolt_L3_flt.VeCPLR_k_PackUnderVolt_L3_flt
            DRA_VeCSCR_k_LinkPVolt_flt_0: accessed-variable=RPort_DidVar_VeCSCR_k_LinkPVolt_flt.VeCSCR_k_LinkPVolt_flt
            DRA_VeCPLR_k_UnderCV_L2_flt_0: accessed-variable=RPort_DidVar_VeCPLR_k_UnderCV_L2_flt.VeCPLR_k_UnderCV_L2_flt
            DRA_VeCPLR_k_UnderCT_L3_flt_0: accessed-variable=RPort_DidVar_VeCPLR_k_UnderCT_L3_flt.VeCPLR_k_UnderCT_L3_flt
            DRA_VeCFLR_k_HeatStuckClose_flt_0: accessed-variable=RPort_DidVar_VeCFLR_k_HeatStuckClose_flt.VeCFLR_k_HeatStuckClose_flt
            DRA_VeSOPR_k_PackOverChrgPower2_flt_0: accessed-variable=RPort_DidVar_VeSOPR_k_PackOverChrgPower2_flt.VeSOPR_k_PackOverChrgPower2_flt
            DRA_VeCPLR_k_PackUnderVolt_L2_flt_0: accessed-variable=RPort_DidVar_VeCPLR_k_PackUnderVolt_L2_flt.VeCPLR_k_PackUnderVolt_L2_flt
            DRA_VeCFLR_k_PrechargeStuckClose_flt_0: accessed-variable=RPort_DidVar_VeCFLR_k_PrechargeStuckClose_flt.VeCFLR_k_PrechargeStuckClose_flt
            DRA_VeLLSR_k_IntEEP_flt_0: accessed-variable=RPort_DidVar_VeLLSR_k_IntEEP_flt.VeLLSR_k_IntEEP_flt
            DRA_VeCFLR_k_PrechargeStuckOpen_flt_0: accessed-variable=RPort_DidVar_VeCFLR_k_PrechargeStuckOpen_flt.VeCFLR_k_PrechargeStuckOpen_flt
            DRA_VeCFLR_k_ConDrvPreCircuit_flt_0: accessed-variable=RPort_DidVar_VeCFLR_k_ConDrvPreCircuit_flt.VeCFLR_k_ConDrvPreCircuit_flt
            DRA_VeCPLR_k_PackOverVolt_L1_flt_0: accessed-variable=RPort_DidVar_VeCPLR_k_PackOverVolt_L1_flt.VeCPLR_k_PackOverVolt_L1_flt
            DRA_VeCPLR_k_DeltaCT_L2_flt_0: accessed-variable=RPort_DidVar_VeCPLR_k_DeltaCT_L2_flt.VeCPLR_k_DeltaCT_L2_flt
            DRA_VeCPLR_k_UnderCT_L1_flt_0: accessed-variable=RPort_DidVar_VeCPLR_k_UnderCT_L1_flt.VeCPLR_k_UnderCT_L1_flt
            DRA_VeCPLR_k_OverCV_L1_flt_0: accessed-variable=RPort_DidVar_VeCPLR_k_OverCV_L1_flt.VeCPLR_k_OverCV_L1_flt
            DRA_VeHVIR_k_MainHVIL2_flt_0: accessed-variable=RPort_DidVar_VeHVIR_k_MainHVIL2_flt.VeHVIR_k_MainHVIL2_flt
            DRA_VeCSCR_k_TempArray_flt_0: accessed-variable=RPort_DidVar_VeCSCR_k_TempArray_flt.VeCSCR_k_TempArray_flt
            DRA_VeCFLR_k_NegativeStuckClose_flt_0: accessed-variable=RPort_DidVar_VeCFLR_k_NegativeStuckClose_flt.VeCFLR_k_NegativeStuckClose_flt
            DRA_VeCPLR_k_OverCV_L4_flt_0: accessed-variable=RPort_DidVar_VeCPLR_k_OverCV_L4_flt.VeCPLR_k_OverCV_L4_flt
            DRA_VeCFLR_k_PreResistorStuckOpen_flt_0: accessed-variable=RPort_DidVar_VeCFLR_k_PreResistorStuckOpen_flt.VeCFLR_k_PreResistorStuckOpen_flt
            DRA_VeTHMR_k_HeatTempRiseFast_flt_0: accessed-variable=RPort_DidVar_VeTHMR_k_HeatTempRiseFast_flt.VeTHMR_k_HeatTempRiseFast_flt
            DRA_VeCPLR_k_OverCT_L4_flt_0: accessed-variable=RPort_DidVar_VeCPLR_k_OverCT_L4_flt.VeCPLR_k_OverCT_L4_flt
            DRA_VeCSCR_k_PCBTempInv_Flt_0: accessed-variable=RPort_DidVar_VeCSCR_k_PCBTempInv_Flt.VeCSCR_k_PCBTempInv_Flt
            DRA_VeCFLR_k_MainFuse1Open_flt_0: accessed-variable=RPort_DidVar_VeCFLR_k_MainFuse1Open_flt.VeCFLR_k_MainFuse1Open_flt
            DRA_VeCFLR_k_MainFuse2Open_flt_0: accessed-variable=RPort_DidVar_VeCFLR_k_MainFuse2Open_flt.VeCFLR_k_MainFuse2Open_flt
        data-receive-point-by-arguments:
          access DataReceivePointByArguments_VariableAccess_F184: accessed-variable=R_DataServices_DspData_F184.Data
        data-send-points:
          78 x access:
            DataSendPoints_VariableAccess_F183: accessed-variable=P_DataServices_DspData_F183.Data
            DataSendPoints_VariableAccess_F184: accessed-variable=P_DataServices_DspData_F184.Data
            DataSendPoints_VariableAccess_F18A: accessed-variable=P_DataServices_DspData_F18A.Data
            DataSendPoints_VariableAccess_F191: accessed-variable=P_DataServices_DspData_F191.Data
            DataSendPoints_VariableAccess_F195: accessed-variable=P_DataServices_DspData_F195.Data
            DataSendPoints_VariableAccess_F199: accessed-variable=P_DataServices_DspData_F199.Data
            DataSendPoints_VariableAccess_0FD1: accessed-variable=P_DataServices_DspData_0FD1.Data
            DataSendPoints_VariableAccess_BE14: accessed-variable=P_DataServices_DspData_BE14.Data
            DataSendPoints_VariableAccess_B787: accessed-variable=P_DataServices_DspData_B787.Data
            DataSendPoints_VariableAccess_B777: accessed-variable=P_DataServices_DspData_B777.Data
            DataSendPoints_VariableAccess_BE57: accessed-variable=P_DataServices_DspData_BE57.Data
            DataSendPoints_VariableAccess_B450: accessed-variable=P_DataServices_DspData_B450.Data
            DataSendPoints_VariableAccess_B467: accessed-variable=P_DataServices_DspData_B467.Data
            DataSendPoints_VariableAccess_B477: accessed-variable=P_DataServices_DspData_B477.Data
            DataSendPoints_VariableAccess_B487: accessed-variable=P_DataServices_DspData_B487.Data
            DataSendPoints_VariableAccess_B497: accessed-variable=P_DataServices_DspData_B497.Data
            DataSendPoints_VariableAccess_F180: accessed-variable=P_DataServices_DspData_F180.Data
            DataSendPoints_VariableAccess_F193: accessed-variable=P_DataServices_DspData_F193.Data
            DataSendPoints_VariableAccess_F198: accessed-variable=P_DataServices_DspData_F198.Data
            DataSendPoints_VariableAccess_102E: accessed-variable=P_DataServices_DspData_102E.Data
            DataSendPoints_VariableAccess_1031: accessed-variable=P_DataServices_DspData_1031.Data
            DataSendPoints_VariableAccess_104F: accessed-variable=P_DataServices_DspData_104F.Data
            DataSendPoints_VariableAccess_1032: accessed-variable=P_DataServices_DspData_1032.Data
            DataSendPoints_VariableAccess_1033: accessed-variable=P_DataServices_DspData_1033.Data
            DataSendPoints_VariableAccess_1035: accessed-variable=P_DataServices_DspData_1035.Data
            DataSendPoints_VariableAccess_1036: accessed-variable=P_DataServices_DspData_1036.Data
            DataSendPoints_VariableAccess_102F: accessed-variable=P_DataServices_DspData_102F.Data
            DataSendPoints_VariableAccess_102D: accessed-variable=P_DataServices_DspData_102D.Data
            DataSendPoints_VariableAccess_1048: accessed-variable=P_DataServices_DspData_1048.Data
            DataSendPoints_VariableAccess_01AC: accessed-variable=P_DataServices_DspData_01AC.Data
            DataSendPoints_VariableAccess_{1037..1039}: accessed-variable=P_DataServices_DspData_{1037..1039}.Data
            DataSendPoints_VariableAccess_103A: accessed-variable=P_DataServices_DspData_103A.Data
            DataSendPoints_VariableAccess_01B1: accessed-variable=P_DataServices_DspData_01B1.Data
            DataSendPoints_VariableAccess_103B: accessed-variable=P_DataServices_DspData_103B.Data
            DataSendPoints_VariableAccess_103C: accessed-variable=P_DataServices_DspData_103C.Data
            DataSendPoints_VariableAccess_103D: accessed-variable=P_DataServices_DspData_103D.Data
            DataSendPoints_VariableAccess_103E: accessed-variable=P_DataServices_DspData_103E.Data
            DataSendPoints_VariableAccess_103F: accessed-variable=P_DataServices_DspData_103F.Data
            DataSendPoints_VariableAccess_{1041..1044}: accessed-variable=P_DataServices_DspData_{1041..1044}.Data
            DataSendPoints_VariableAccess_01BB: accessed-variable=P_DataServices_DspData_01BB.Data
            DataSendPoints_VariableAccess_01BC: accessed-variable=P_DataServices_DspData_01BC.Data
            DataSendPoints_VariableAccess_01BD: accessed-variable=P_DataServices_DspData_01BD.Data
            DataSendPoints_VariableAccess_01BF: accessed-variable=P_DataServices_DspData_01BF.Data
            DataSendPoints_VariableAccess_01C0: accessed-variable=P_DataServices_DspData_01C0.Data
            DataSendPoints_VariableAccess_{1045..1047}: accessed-variable=P_DataServices_DspData_{1045..1047}.Data
            DataSendPoints_VariableAccess_01D9: accessed-variable=P_DataServices_DspData_01D9.Data
            DataSendPoints_VariableAccess_01DA: accessed-variable=P_DataServices_DspData_01DA.Data
            DataSendPoints_VariableAccess_01DC: accessed-variable=P_DataServices_DspData_01DC.Data
            DataSendPoints_VariableAccess_01DD: accessed-variable=P_DataServices_DspData_01DD.Data
            DataSendPoints_VariableAccess_01E4: accessed-variable=P_DataServices_DspData_01E4.Data
            DataSendPoints_VariableAccess_01E5: accessed-variable=P_DataServices_DspData_01E5.Data
            DataSendPoints_VariableAccess_1049: accessed-variable=P_DataServices_DspData_1049.Data
            DataSendPoints_VariableAccess_01E{7..9}: accessed-variable=P_DataServices_DspData_01E{7..9}.Data
            DataSendPoints_VariableAccess_01EA: accessed-variable=P_DataServices_DspData_01EA.Data
            DataSendPoints_VariableAccess_104A: accessed-variable=P_DataServices_DspData_104A.Data
            DataSendPoints_VariableAccess_104B: accessed-variable=P_DataServices_DspData_104B.Data
            DataSendPoints_VariableAccess_104E: accessed-variable=P_DataServices_DspData_104E.Data
            DSP_Data_0: accessed-variable=PPort_DID_F1A9.Data
            DSP_Data_1: accessed-variable=PPort_DID_F1AA.Data
            DSP_Data_2: accessed-variable=PPort_DID_F1A5.Data
            DSP_Data_3: accessed-variable=PPort_DID_F1F0.Data
            DataSendPoints_VariableAccess_F192: accessed-variable=P_DataServices_DspData_F192.Data
            DataSendPoints_VariableAccess_F188: accessed-variable=P_DataServices_DspData_F188.Data
            DataSendPoints_VariableAccess_1034: accessed-variable=P_DataServices_DspData_1034.Data
            DataSendPoints_VariableAccess_1000: accessed-variable=P_DataServices_DspData_1000.Data
            DataSendPoints_VariableAccess_1020: accessed-variable=P_DataServices_DspData_1020.Data
            DataSendPoints_VariableAccess_1040: accessed-variable=P_DataServices_DspData_1040.Data
            DataSendPoints_VariableAccess_1030: accessed-variable=P_DataServices_DspData_1030.Data
            DataSendPoints_VariableAccess_F194: accessed-variable=P_DataServices_DspData_F194.Data
      runnable RE_DIDs_10ms: symbol=RE_DID_Process10ms
        data-send-points:
          11 x access:
            DataSendPoints_VariableAccess_BD{01..10}: accessed-variable=P_DataServices_DspData_BD{01..10}.Data
            DataSendPoints_VariableAccess_01BE: accessed-variable=P_DataServices_DspData_01BE.Data
      swc service dependency Srv_NvM_DID_01FF: assigned-datas=role-based-data-assignment={role=ramBlock, used-pim=PIM_Did_01FF}
        service-needs:
          nv block needs NeDIDR_PartNum_01FF: resistant-to-changed-sw=true, restore-at-start=true, store-at-shutdown=true
  5 x impl type:
    DcmDspDidSize_DspData_01FF: category=ARRAY
      element DataArray: array-size=34, array-size-semantics=FIXED-SIZE, implementation-data-type=uint8
    DcmDspDidSize_DspData_F190: category=ARRAY
      element DataArray: array-size=17, array-size-semantics=FIXED-SIZE, implementation-data-type=uint8
    DcmDspDidSize_DspData_104D: category=ARRAY
      element DataArray: array-size=24, array-size-semantics=FIXED-SIZE, implementation-data-type=uint8
    DcmDspDidSize_DspData_104C: implementation-data-type=uint8
    DcmDspDidSize_DspData_F187: category=ARRAY
      element DataArray: array-size=13, array-size-semantics=FIXED-SIZE, implementation-data-type=uint8
